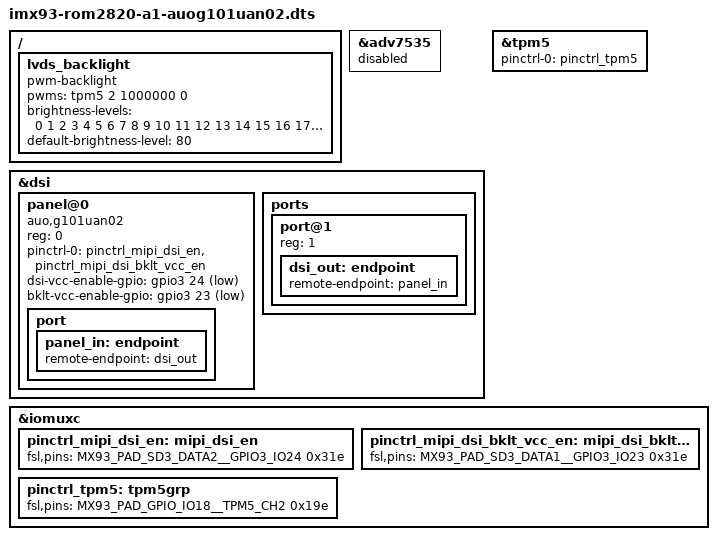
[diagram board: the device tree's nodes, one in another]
// SPDX-License-Identifier: (GPL-2.0+ OR MIT)
/*
 * Copyright 2019 NXP
 */

#include "imx93-rom2820-a1.dts"

/ {
	lvds_backlight: lvds_backlight {
		compatible = "pwm-backlight";
		pwms = <&tpm5 2 1000000 0>;
		status = "okay";

		brightness-levels = < 0  1  2  3  4  5  6  7  8  9
				     10 11 12 13 14 15 16 17 18 19
				     20 21 22 23 24 25 26 27 28 29
				     30 31 32 33 34 35 36 37 38 39
				     40 41 42 43 44 45 46 47 48 49
				     50 51 52 53 54 55 56 57 58 59
				     60 61 62 63 64 65 66 67 68 69
				     70 71 72 73 74 75 76 77 78 79
				     80 81 82 83 84 85 86 87 88 89
				     90 91 92 93 94 95 96 97 98 99
				    100>;
		default-brightness-level = <80>;
	};
};

&adv7535 {
        status = "disabled";
};

/delete-node/ &dsi_to_adv7535;
/delete-node/ &adv7535_to_dsi;

&dsi {
	#address-cells = <1>;
        #size-cells = <0>;

	status = "okay";

	panel@0 {
		compatible = "auo,g101uan02";
		reg = <0>;
		pinctrl-0 = <&pinctrl_mipi_dsi_en &pinctrl_mipi_dsi_bklt_vcc_en>;
		dsi-vcc-enable-gpio =  <&gpio3 24 GPIO_ACTIVE_LOW>;     /* LCD_VDD_EN */
		bklt-vcc-enable-gpio =  <&gpio3 23 GPIO_ACTIVE_LOW>;     /* VDD_BKLT1_EN */
		
		 port {
                        panel_in: endpoint {
                                remote-endpoint = <&dsi_out>;
                        };
                };

	};

	ports {
                port@1 {
                        reg = <1>;

                        dsi_out: endpoint {
                                remote-endpoint = <&panel_in>;
                        };
                };
        };

};

&tpm5 {
        pinctrl-names = "default";
        pinctrl-0 = <&pinctrl_tpm5>;
        status = "okay";
};

&iomuxc {
	pinctrl_mipi_dsi_en: mipi_dsi_en {
		fsl,pins = <
		    MX93_PAD_SD3_DATA2__GPIO3_IO24		0x31e    /* LCD_VDD_EN */
		>;
	};

	pinctrl_mipi_dsi_bklt_vcc_en: mipi_dsi_bklt_vcc_en_grp {
		fsl,pins = <
		    MX93_PAD_SD3_DATA1__GPIO3_IO23		0x31e    /* VDD_BKLT1_EN */
		>;
	};

	pinctrl_tpm5: tpm5grp {
             fsl,pins = <
		    MX93_PAD_GPIO_IO18__TPM5_CH2		0x19e
             >;
	};
};
